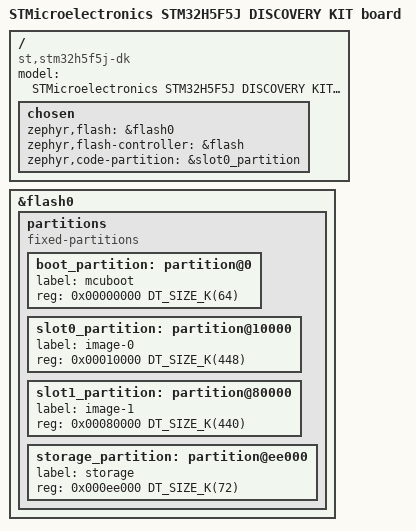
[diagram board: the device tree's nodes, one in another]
/*
 * Copyright (c) 2026 STMicroelectronics
 *
 * SPDX-License-Identifier: Apache-2.0
 */

/dts-v1/;
#include "stm32h5f5j_dk-common.dtsi"

/ {
	model = "STMicroelectronics STM32H5F5J DISCOVERY KIT board";
	compatible = "st,stm32h5f5j-dk";

	chosen {
		zephyr,flash = &flash0;
		zephyr,flash-controller = &flash;
		zephyr,code-partition = &slot0_partition;
	};
};

&flash0 {
	partitions {
		compatible = "fixed-partitions";
		#address-cells = <1>;
		#size-cells = <1>;

		/* Set the partitions with first MB to make use of the whole Bank1 */
		boot_partition: partition@0 {
			label = "mcuboot";
			reg = <0x00000000 DT_SIZE_K(64)>;
		};

		slot0_partition: partition@10000 {
			label = "image-0";
			reg = <0x00010000 DT_SIZE_K(448)>;
		};

		slot1_partition: partition@80000 {
			label = "image-1";
			reg = <0x00080000 DT_SIZE_K(440)>;
		};

		/* Set 72KB of storage at the end of Bank1 */
		storage_partition: partition@ee000 {
			label = "storage";
			reg = <0x000ee000 DT_SIZE_K(72)>;
		};
	};
};
